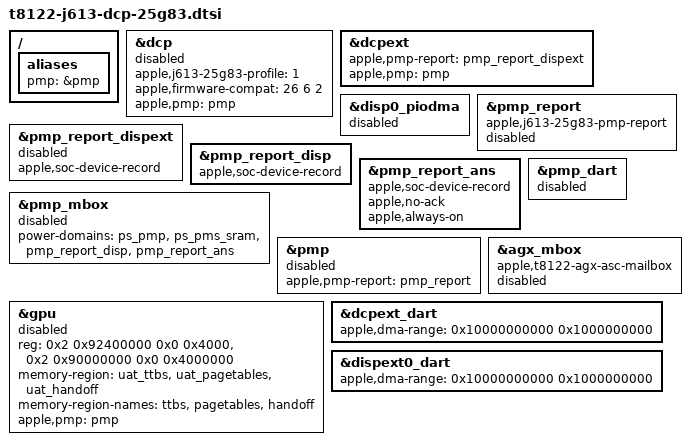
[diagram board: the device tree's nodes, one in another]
// SPDX-License-Identifier: GPL-2.0+ OR MIT
/* J613 25G83: inherit the hardware wiring, select a separate firmware ABI.
 * No board tunables or DMA mappings are embedded. The boot loader passes
 * this Mac's PMP values and validates the running display's mappings.
 */
/ {
	aliases {
		pmp = &pmp;
	};
};

&dcp {
	apple,j613-25g83-profile = <1>;
	apple,firmware-compat = <26 6 2>;
	apple,pmp = <&pmp>;
	/* The 26.6 firmware takes its PMP through apple,pmp, not a request. */
	/delete-property/ apple,pmp-report;
	/delete-property/ clocks;
	status = "disabled";
};

&dcpext {
	apple,pmp-report = <&pmp_report_dispext>;
	apple,pmp = <&pmp>;
};

&disp0_piodma {
	status = "disabled";
};

/* Reuse the complete Asahi PMP topology, with this profile left disabled. */
&pmp_report {
	compatible = "apple,j613-25g83-pmp-report";
	/* The native PMP names its report instead (apple,pmp-report). */
	/delete-property/ apple,pmp;
	status = "disabled";
};

/* This profile requests only DISP and ANS until external admission succeeds. */
&pmp_report_dispext {
	apple,soc-device-record;
	status = "disabled";
};

&pmp_report_disp {
	apple,soc-device-record;
};

&pmp_report_ans {
	apple,soc-device-record;
	apple,no-ack;
	apple,always-on;
};

&pmp_dart {
	status = "disabled";
};

&pmp_mbox {
	power-domains = <&ps_pmp>, <&ps_pms_sram>,
			<&pmp_report_disp>, <&pmp_report_ans>;
	status = "disabled";
};

&pmp {
	apple,pmp-report = <&pmp_report>;
	status = "disabled";
};

/* The 25G83 GPU uses the native ASC mailbox and the same PMP supplier.
 * Firmware mappings and calibration are supplied by the boot loader.
 */
&agx_mbox {
	compatible = "apple,t8122-agx-asc-mailbox", "apple,asc-mailbox-v4";
	status = "disabled";
};

/*
 * G16G admission (g16_resources.rs) requires exactly six memory regions named
 * ttbs, pagetables, handoff, shared-l2, fw-text and fw-data, in that order.
 * The boot loader's 25G83 handoff replaces entries with those names and keeps
 * any other entry ahead of them, so the generic "pagetables-l2" entry would
 * leave seven regions and admission would fail with -EINVAL. List only the
 * entries the boot loader replaces; it reserves uat-pagetables-l2 itself and
 * links it as shared-l2.
 *
 * The ASC window is the 16 KiB ASC page that G16G maps exclusively. The
 * generic 0x6c000 window also covers the GFX mailbox at +0x8000, which the
 * mailbox driver has already claimed, so the exclusive mapping would fail
 * with -EBUSY.
 */
&gpu {
	reg = <0x2 0x92400000 0x0 0x4000>,
	      <0x2 0x90000000 0x0 0x4000000>;
	memory-region = <&uat_ttbs>, <&uat_pagetables>, <&uat_handoff>;
	memory-region-names = "ttbs", "pagetables", "handoff";
	apple,pmp = <&pmp>;
	status = "disabled";
};

/* Native26 firmware and PIODMA use the same 1-TiB alias as the panel. */
&dcpext_dart {
	apple,dma-range = /bits/ 64 <0x10000000000 0x1000000000>;
};

&dispext0_dart {
	apple,dma-range = /bits/ 64 <0x10000000000 0x1000000000>;
};
